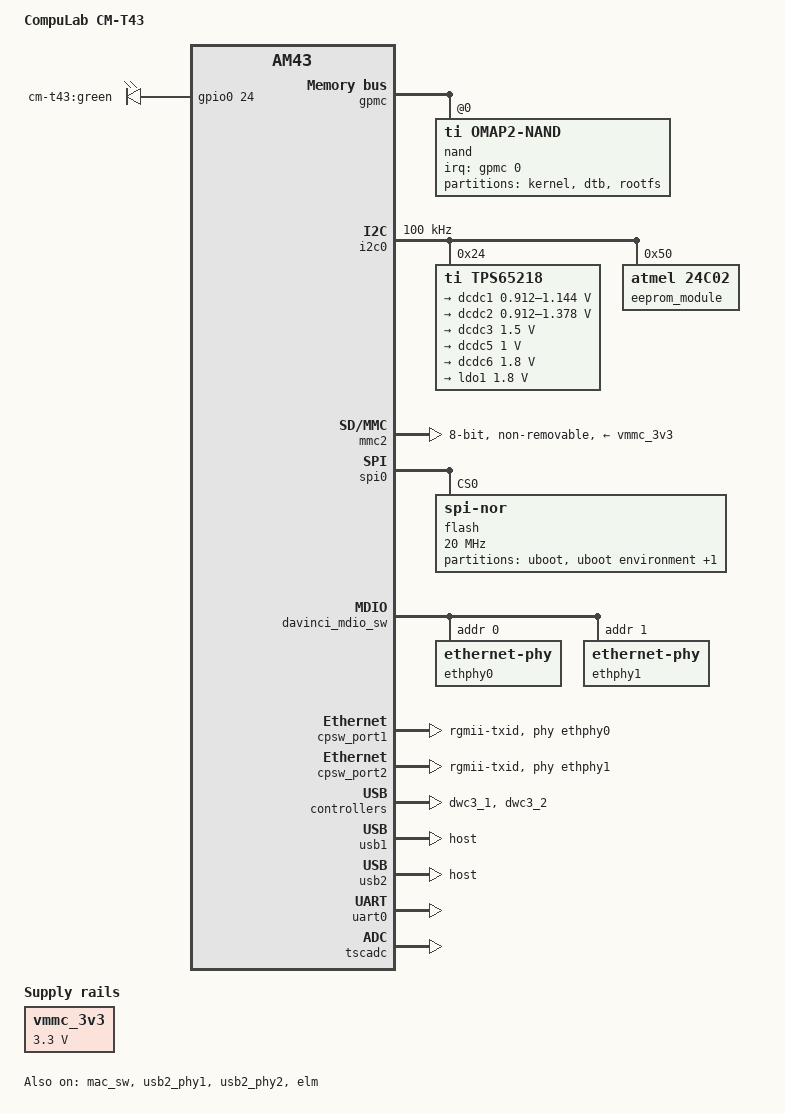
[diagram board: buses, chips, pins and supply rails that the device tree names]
/dts-v1/;
#include <dt-bindings/pinctrl/am43xx.h>
#include <dt-bindings/gpio/gpio.h>
#include <dt-bindings/interrupt-controller/irq.h>
#include "am4372.dtsi"
/ {
	model = "CompuLab CM-T43";
	compatible = "compulab,am437x-cm-t43", "ti,am4372", "ti,am43";
	leds {
		compatible = "gpio-leds";
		ledb {
			label = "cm-t43:green";
			gpios = <&gpio0 24 GPIO_ACTIVE_HIGH>;
			linux,default-trigger = "heartbeat";
		};
	};
	vmmc_3v3: fixedregulator-v3_3 {
		compatible = "regulator-fixed";
		regulator-name = "vmmc_3v3";
		regulator-min-microvolt = <3300000>;
		regulator-max-microvolt = <3300000>;
		regulator-always-on;
		enable-active-high;
	};
};
&am43xx_pinmux {
	pinctrl-names = "default";
	pinctrl-0 = <&cm_t43_led_pins>;
	cm_t43_led_pins: cm-t43-led-pins {
		pinctrl-single,pins = <
			AM4372_IOPAD(0xa78, MUX_MODE7)
		>;
	};
	i2c0_pins: i2c0-pins {
		pinctrl-single,pins = <
			AM4372_IOPAD(0x988, PIN_INPUT_PULLUP | SLEWCTRL_FAST | MUX_MODE0)   
			AM4372_IOPAD(0x98c, PIN_INPUT_PULLUP | SLEWCTRL_FAST | MUX_MODE0)   
		>;
	};
	emmc_pins: emmc-pins {
		pinctrl-single,pins = <
			AM4372_IOPAD(0x820, PIN_INPUT_PULLUP | MUX_MODE2)  
			AM4372_IOPAD(0x824, PIN_INPUT_PULLUP | MUX_MODE2)  
			AM4372_IOPAD(0x828, PIN_INPUT_PULLUP | MUX_MODE2)  
			AM4372_IOPAD(0x82c, PIN_INPUT_PULLUP | MUX_MODE2)  
			AM4372_IOPAD(0x830, PIN_INPUT_PULLUP | MUX_MODE2)  
			AM4372_IOPAD(0x834, PIN_INPUT_PULLUP | MUX_MODE2)  
			AM4372_IOPAD(0x838, PIN_INPUT_PULLUP | MUX_MODE2)  
			AM4372_IOPAD(0x83c, PIN_INPUT_PULLUP | MUX_MODE2)  
			AM4372_IOPAD(0x880, PIN_INPUT_PULLUP | MUX_MODE2)  
			AM4372_IOPAD(0x884, PIN_INPUT_PULLUP | MUX_MODE2)  
		>;
	};
	spi0_pins: spi0-pins {
		pinctrl-single,pins = <
			AM4372_IOPAD(0x950, PIN_INPUT | MUX_MODE0)  
			AM4372_IOPAD(0x954, PIN_INPUT | MUX_MODE0)  
			AM4372_IOPAD(0x958, PIN_OUTPUT | MUX_MODE0)  
			AM4372_IOPAD(0x95C, PIN_OUTPUT | MUX_MODE0)  
		>;
	};
	nand_flash_x8: nand-flash-x8-pins {
		pinctrl-single,pins = <
			AM4372_IOPAD(0x800, PIN_INPUT | PULL_DISABLE | MUX_MODE0)
			AM4372_IOPAD(0x804, PIN_INPUT | PULL_DISABLE | MUX_MODE0)
			AM4372_IOPAD(0x808, PIN_INPUT | PULL_DISABLE | MUX_MODE0)
			AM4372_IOPAD(0x80c, PIN_INPUT | PULL_DISABLE | MUX_MODE0)
			AM4372_IOPAD(0x810, PIN_INPUT | PULL_DISABLE | MUX_MODE0)
			AM4372_IOPAD(0x814, PIN_INPUT | PULL_DISABLE | MUX_MODE0)
			AM4372_IOPAD(0x818, PIN_INPUT | PULL_DISABLE | MUX_MODE0)
			AM4372_IOPAD(0x81c, PIN_INPUT | PULL_DISABLE | MUX_MODE0)
			AM4372_IOPAD(0x870, PIN_INPUT_PULLUP  | MUX_MODE0)
			AM4372_IOPAD(0x874, PIN_OUTPUT_PULLUP | MUX_MODE0)
			AM4372_IOPAD(0x87c, PIN_OUTPUT_PULLUP | MUX_MODE0)
			AM4372_IOPAD(0x898, PIN_OUTPUT_PULLDOWN | MUX_MODE0)
			AM4372_IOPAD(0x894, PIN_OUTPUT_PULLDOWN | MUX_MODE0)
			AM4372_IOPAD(0x890, PIN_OUTPUT_PULLDOWN | MUX_MODE0)
			AM4372_IOPAD(0x89c, PIN_OUTPUT_PULLDOWN | MUX_MODE0)
		>;
	};
	cpsw_default: cpsw-default-pins {
		pinctrl-single,pins = <
			AM4372_IOPAD(0x914, PIN_OUTPUT_PULLDOWN | MUX_MODE2)	 
			AM4372_IOPAD(0x918, PIN_INPUT_PULLDOWN | MUX_MODE2)	 
			AM4372_IOPAD(0x91c, PIN_OUTPUT_PULLDOWN | MUX_MODE2)	 
			AM4372_IOPAD(0x920, PIN_OUTPUT_PULLDOWN | MUX_MODE2)	 
			AM4372_IOPAD(0x924, PIN_OUTPUT_PULLDOWN | MUX_MODE2)	 
			AM4372_IOPAD(0x928, PIN_OUTPUT_PULLDOWN | MUX_MODE2)	 
			AM4372_IOPAD(0x92c, PIN_OUTPUT_PULLDOWN | MUX_MODE2)	 
			AM4372_IOPAD(0x930, PIN_INPUT_PULLDOWN | MUX_MODE2)	 
			AM4372_IOPAD(0x934, PIN_INPUT_PULLDOWN | MUX_MODE2)	 
			AM4372_IOPAD(0x938, PIN_INPUT_PULLDOWN | MUX_MODE2)	 
			AM4372_IOPAD(0x93c, PIN_INPUT_PULLDOWN | MUX_MODE2)	 
			AM4372_IOPAD(0x940, PIN_INPUT_PULLDOWN | MUX_MODE2)	 
			AM4372_IOPAD(0xa74, MUX_MODE3)
			AM4372_IOPAD(0x840, PIN_OUTPUT_PULLDOWN | MUX_MODE2)	 
			AM4372_IOPAD(0x844, PIN_INPUT_PULLDOWN  | MUX_MODE2)	 
			AM4372_IOPAD(0x848, PIN_OUTPUT_PULLDOWN | MUX_MODE2)	 
			AM4372_IOPAD(0x84c, PIN_OUTPUT_PULLDOWN | MUX_MODE2)	 
			AM4372_IOPAD(0x850, PIN_OUTPUT_PULLDOWN | MUX_MODE2)	 
			AM4372_IOPAD(0x854, PIN_OUTPUT_PULLDOWN | MUX_MODE2)	 
			AM4372_IOPAD(0x858, PIN_OUTPUT_PULLDOWN | MUX_MODE2)	 
			AM4372_IOPAD(0x85c, PIN_INPUT_PULLDOWN  | MUX_MODE2)	 
			AM4372_IOPAD(0x860, PIN_INPUT_PULLDOWN  | MUX_MODE2)	 
			AM4372_IOPAD(0x864, PIN_INPUT_PULLDOWN  | MUX_MODE2)	 
			AM4372_IOPAD(0x868, PIN_INPUT_PULLDOWN  | MUX_MODE2)	 
			AM4372_IOPAD(0x86c, PIN_INPUT_PULLDOWN  | MUX_MODE2)	 
			AM4372_IOPAD(0xa38, MUX_MODE7)
		>;
	};
	davinci_mdio_default: davinci-mdio-default-pins {
		pinctrl-single,pins = <
			AM4372_IOPAD(0x948, PIN_INPUT_PULLUP | SLEWCTRL_FAST | MUX_MODE0)	 
			AM4372_IOPAD(0x94c, PIN_OUTPUT_PULLUP | MUX_MODE0)			 
		>;
	};
};
&gpmc {
	status = "okay";
	pinctrl-names = "default";
	pinctrl-0 = <&nand_flash_x8>;
	ranges = <0 0 0x08000000 0x1000000>;
	nand@0,0 {
		compatible = "ti,omap2-nand";
		reg = <0 0 4>;		 
		interrupt-parent = <&gpmc>;
		interrupts = <0 IRQ_TYPE_NONE>,  
			     <1 IRQ_TYPE_NONE>;	 
		ti,nand-ecc-opt = "bch8";
		ti,elm-id = <&elm>;
		nand-bus-width = <8>;
		gpmc,device-width = <1>;
		gpmc,sync-clk-ps = <0>;
		gpmc,cs-on-ns = <0>;
		gpmc,cs-rd-off-ns = <44>;
		gpmc,cs-wr-off-ns = <44>;
		gpmc,adv-on-ns = <6>;
		gpmc,adv-rd-off-ns = <34>;
		gpmc,adv-wr-off-ns = <44>;
		gpmc,we-on-ns = <0>;
		gpmc,we-off-ns = <40>;
		gpmc,oe-on-ns = <0>;
		gpmc,oe-off-ns = <54>;
		gpmc,access-ns = <64>;
		gpmc,rd-cycle-ns = <82>;
		gpmc,wr-cycle-ns = <82>;
		gpmc,bus-turnaround-ns = <0>;
		gpmc,cycle2cycle-delay-ns = <0>;
		gpmc,clk-activation-ns = <0>;
		gpmc,wr-access-ns = <40>;
		gpmc,wr-data-mux-bus-ns = <0>;
		#address-cells = <1>;
		#size-cells = <1>;
		partition@0 {
			label = "kernel";
			reg = <0x0 0x00980000>;
		};
		partition@980000 {
			label = "dtb";
			reg = <0x00980000 0x00080000>;
		};
		partition@a00000 {
			label = "rootfs";
			reg = <0x00a00000 0x0>;
		};
	};
};
&i2c0 {
	status = "okay";
	pinctrl-names = "default";
	pinctrl-0 = <&i2c0_pins>;
	clock-frequency = <100000>;
	tps65218: tps65218@24 {
		compatible = "ti,tps65218";
		reg = <0x24>;
		interrupts = <GIC_SPI 7 IRQ_TYPE_LEVEL_HIGH>;  
		interrupt-parent = <&gic>;
		interrupt-controller;
		#interrupt-cells = <2>;
		dcdc1: regulator-dcdc1 {
			regulator-name = "vdd_core";
			regulator-min-microvolt = <912000>;
			regulator-max-microvolt = <1144000>;
			regulator-boot-on;
			regulator-always-on;
		};
		dcdc2: regulator-dcdc2 {
			regulator-name = "vdd_mpu";
			regulator-min-microvolt = <912000>;
			regulator-max-microvolt = <1378000>;
			regulator-boot-on;
			regulator-always-on;
		};
		dcdc3: regulator-dcdc3 {
			regulator-name = "vdcdc3";
			regulator-suspend-enable;
			regulator-min-microvolt = <1500000>;
			regulator-max-microvolt = <1500000>;
			regulator-boot-on;
			regulator-always-on;
		};
		dcdc5: regulator-dcdc5 {
			regulator-name = "v1_0bat";
			regulator-min-microvolt = <1000000>;
			regulator-max-microvolt = <1000000>;
			regulator-boot-on;
			regulator-always-on;
		};
		dcdc6: regulator-dcdc6 {
			regulator-name = "v1_8bat";
			regulator-min-microvolt = <1800000>;
			regulator-max-microvolt = <1800000>;
			regulator-boot-on;
			regulator-always-on;
		};
		ldo1: regulator-ldo1 {
			regulator-min-microvolt = <1800000>;
			regulator-max-microvolt = <1800000>;
			regulator-boot-on;
			regulator-always-on;
		};
	};
	eeprom_module: at24@50 {
		compatible = "atmel,24c02";
		reg = <0x50>;
		pagesize = <16>;
	};
};
&gpio0 {
	status = "okay";
};
&gpio1 {
	status = "okay";
};
&gpio2 {
	status = "okay";
};
&gpio3 {
	status = "okay";
};
&gpio4 {
	status = "okay";
};
&gpio5 {
	status = "okay";
};
&mmc2 {
	status = "okay";
	pinctrl-names = "default";
	pinctrl-0 = <&emmc_pins>;
	vmmc-supply = <&vmmc_3v3>;
	bus-width = <8>;
	non-removable;
};
&spi0 {
	status = "okay";
	pinctrl-names = "default";
	pinctrl-0 = <&spi0_pins>;
	dmas = <&edma 16 0
		&edma 17 0>;
	dma-names = "tx0", "rx0";
	flash: flash@0 {
		#address-cells = <1>;
		#size-cells = <1>;
		compatible = "jedec,spi-nor";
		reg = <0>;
		spi-max-frequency = <20000000>;
		partition@0 {
			label = "uboot";
			reg = <0x0 0xc0000>;
		};
		partition@c0000 {
			label = "uboot environment";
			reg = <0xc0000 0x40000>;
		};
		partition@100000 {
			label = "reserved";
			reg = <0x100000 0x100000>;
		};
	};
};
&mac_sw {
	pinctrl-names = "default";
	pinctrl-0 = <&cpsw_default>;
	status = "okay";
};
&davinci_mdio_sw {
	pinctrl-names = "default";
	pinctrl-0 = <&davinci_mdio_default>;
	ethphy0: ethernet-phy@0 {
		reg = <0>;
	};
	ethphy1: ethernet-phy@1 {
		reg = <1>;
	};
};
&cpsw_port1 {
	phy-handle = <&ethphy0>;
	phy-mode = "rgmii-txid";
	ti,dual-emac-pvid = <1>;
};
&cpsw_port2 {
	phy-handle = <&ethphy1>;
	phy-mode = "rgmii-txid";
	ti,dual-emac-pvid = <2>;
};
&dwc3_1 {
	status = "okay";
};
&usb2_phy1 {
	status = "okay";
};
&usb1 {
	dr_mode = "host";
	status = "okay";
};
&dwc3_2 {
	status = "okay";
};
&usb2_phy2 {
	status = "okay";
};
&usb2 {
	dr_mode = "host";
	status = "okay";
	interrupts = <GIC_SPI 174 IRQ_TYPE_LEVEL_HIGH>,
		     <GIC_SPI 174 IRQ_TYPE_LEVEL_HIGH>,
		     <GIC_SPI 178 IRQ_TYPE_LEVEL_HIGH>;
	interrupt-names = "peripheral", "host", "otg";
};
&elm {
	status = "okay";
};
&uart0 {
	status = "okay";
};
&tscadc {
	status = "okay";
	tsc {
		ti,wires = <4>;
		ti,x-plate-resistance = <200>;
		ti,coordinate-readouts = <5>;
		ti,wire-config = <0x00 0x11 0x22 0x33>;
	};
	adc {
		ti,adc-channels = <4 5 6 7>;
	};
};
&cpu {
	cpu0-supply = <&dcdc2>;
	operating-points = <1000000 1330000>,
			   <800000 1260000>,
			   <720000 1200000>,
			   <600000 1100000>,
			   <300000 950000>;
};
&pruss1_mdio {
	status = "disabled";
};
